# TMS320F280049 register map
Vendor: Texas Instruments; Series: C2000 F28004x; File version: 0.2.0-generated
Registers are 16-bit, read-write, reset 0x0 unless marked. A register's access mark holds for its fields unless they carry their own. Offsets are from the block's base; [hi:lo] are bit positions.

## EQEP1REGS — EQEP Registers
Base 0x0000A200
Same registers: EQEP2REGS 0x0000A280
0x00 QPOSCNT 32-bit — Position Counter
  [31] QPOSCNT
0x04 QPOSINIT 32-bit — Position Counter Init
  [31] QPOSINIT
0x08 QPOSMAX 32-bit — Maximum Position Count
  [31] QPOSMAX
0x0C QPOSCMP 32-bit — Position Compare
  [31] QPOSCMP
0x10 QPOSILAT 32-bit — Index Position Latch
  [31] QPOSILAT
0x14 QPOSSLAT 32-bit — Strobe Position Latch
  [31] QPOSSLAT
0x18 QPOSLAT 32-bit — Position Latch
  [31] QPOSLAT
0x1C QUTMR 32-bit — QEP Unit Timer
  [31] QUTMR
0x20 QUPRD 32-bit — QEP Unit Period
  [31] QUPRD
0x24 QWDTMR — QEP Watchdog Timer
  [15] QWDTMR
0x26 QWDPRD — QEP Watchdog Period
  [15] QWDPRD
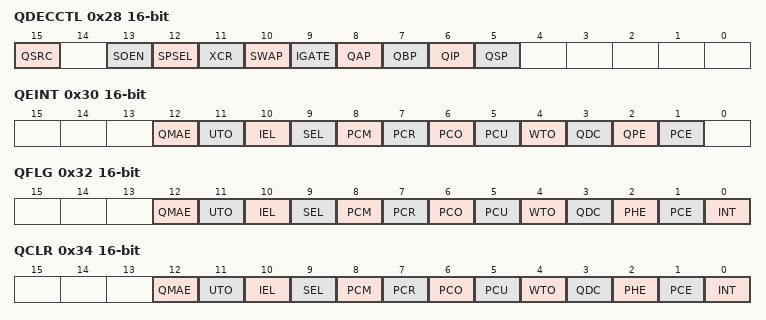
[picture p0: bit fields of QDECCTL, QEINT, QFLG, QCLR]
0x28 QDECCTL — Quadrature Decoder Control
  [15] QSRC — Position-counter source selection
  [13] SOEN — Sync output-enable
  [12] SPSEL — Sync output pin selection
  [11] XCR — External Clock Rate
  [10] SWAP — CLK/DIR Signal Source for Position Counter
  [9] IGATE — Index pulse gating option
  [8] QAP — QEPA input polarity
  [7] QBP — QEPB input polarity
  [6] QIP — QEPI input polarity
  [5] QSP — QEPS input polarity
0x2A QEPCTL — QEP Control
  [15] FREE_SOFT — Emulation mode
  [14:13] PCRM — Postion counter reset
  [12:11] SEI — Strobe event init
  [10:9] IEI — Index event init of position count
  [7] SWI — Software init position counter
  [6] SEL — Strobe event latch
  [6:5] IEL — Index event latch
  [3] QPEN — Quadrature postotion counter enable
  [2] QCLM — QEP capture latch mode
  [1] UTE — QEP unit timer enable
  [0] WDE — QEP watchdog enable
0x2C QCAPCTL — Qaudrature Capture Control
  [15] CEN — Enable eQEP capture
  [8:6] CCPS — eQEP capture timer clock prescaler
  [6:3] UPPS — Unit position event prescaler
0x2E QPOSCTL — Position Compare Control
  [15] PCSHDW — Position compare of shadow enable
  [14] PCLOAD — Position compare of shadow load
  [13] PCPOL — Polarity of sync output
  [12] PCE — Position compare enable/disable
  [15:11] PCSPW — Position compare sync pulse width
0x30 QEINT — QEP Interrupt Control
  [12] QMAE — QMA error interrupt enable
  [11] UTO — Unit time out interrupt enable
  [10] IEL — Index event latch interrupt enable
  [9] SEL — Strobe event latch interrupt enable
  [8] PCM — Position-compare match interrupt enable
  [7] PCR — Position-compare ready interrupt enable
  [6] PCO — Position counter overflow interrupt enable
  [5] PCU — Position counter underflow interrupt enable
  [4] WTO — Watchdog time out interrupt enable
  [3] QDC — Quadrature direction change interrupt enable
  [2] QPE — Quadrature phase error interrupt enable
  [1] PCE — Position counter error interrupt enable
0x32 QFLG — QEP Interrupt Flag
  [12] QMAE — QMA error interrupt flag
  [11] UTO — Unit time out interrupt flag
  [10] IEL — Index event latch interrupt flag
  [9] SEL — Strobe event latch interrupt flag
  [8] PCM — eQEP compare match event interrupt flag
  [7] PCR — Position-compare ready interrupt flag
  [6] PCO — Position counter overflow interrupt flag
  [5] PCU — Position counter underflow interrupt flag
  [4] WTO — Watchdog timeout interrupt flag
  [3] QDC — Quadrature direction change interrupt flag
  [2] PHE — Quadrature phase error interrupt flag
  [1] PCE — Position counter error interrupt flag
  [0] INT — Global interrupt status flag
0x34 QCLR — QEP Interrupt Clear
  [12] QMAE — Clear QMA error interrupt flag
  [11] UTO — Clear unit time out interrupt flag
  [10] IEL — Clear index event latch interrupt flag
  [9] SEL — Clear strobe event latch interrupt flag
  [8] PCM — Clear eQEP compare match event interrupt flag
  [7] PCR — Clear position-compare ready interrupt flag
  [6] PCO — Clear position counter overflow interrupt flag
  [5] PCU — Clear position counter underflow interrupt flag
  [4] WTO — Clear watchdog timeout interrupt flag
  [3] QDC — Clear quadrature direction change interrupt flag
  [2] PHE — Clear quadrature phase error interrupt flag
  [1] PCE — Clear position counter error interrupt flag
  [0] INT — Global interrupt clear flag
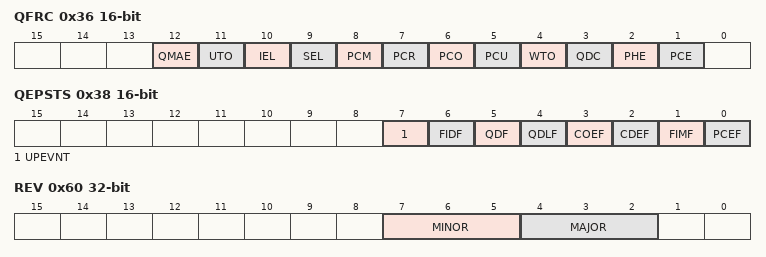
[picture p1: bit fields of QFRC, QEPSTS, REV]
0x36 QFRC — QEP Interrupt Force
  [12] QMAE — Force QMA error interrupt
  [11] UTO — Force unit time out interrupt
  [10] IEL — Force index event latch interrupt
  [9] SEL — Force strobe event latch interrupt
  [8] PCM — Force position-compare match interrupt
  [7] PCR — Force position-compare ready interrupt
  [6] PCO — Force position counter overflow interrupt
  [5] PCU — Force position counter underflow interrupt
  [4] WTO — Force watchdog time out interrupt
  [3] QDC — Force quadrature direction change interrupt
  [2] PHE — Force quadrature phase error interrupt
  [1] PCE — Force position counter error interrupt
0x38 QEPSTS — QEP Status
  [7] UPEVNT — Unit position event flag
  [6] FIDF — The first index marker
  [5] QDF — Quadrature direction flag
  [4] QDLF — eQEP direction latch flag
  [3] COEF — Capture overflow error flag
  [2] CDEF — Capture direction error flag
  [1] FIMF — First index marker flag
  [0] PCEF — Position counter error flag.
0x3A QCTMR — QEP Capture Timer
  [15] QCTMR — This register provides time base for edge capture unit.
0x3C QCPRD — QEP Capture Period
  [15] QCPRD — Period count value between eQEP position events
0x3E QCTMRLAT — QEP Capture Latch
  [15] QCTMRLAT — The eQEP capture timer latch value
0x40 QCPRDLAT — QEP Capture Period Latch
  [15] QCPRDLAT — eQEP capture period latch value
0x60 REV 32-bit — QEP Revision Number
  [7:5] MINOR — Minor Revision Number
  [4:2] MAJOR — Major Revision Number
0x64 QEPSTROBESEL 32-bit — QEP Strobe select register
  [2:1] STROBESEL — QMA Mode Select
0x68 QMACTRL 32-bit — QMA Control register
  [4:2] MODE — QMA Mode Select
